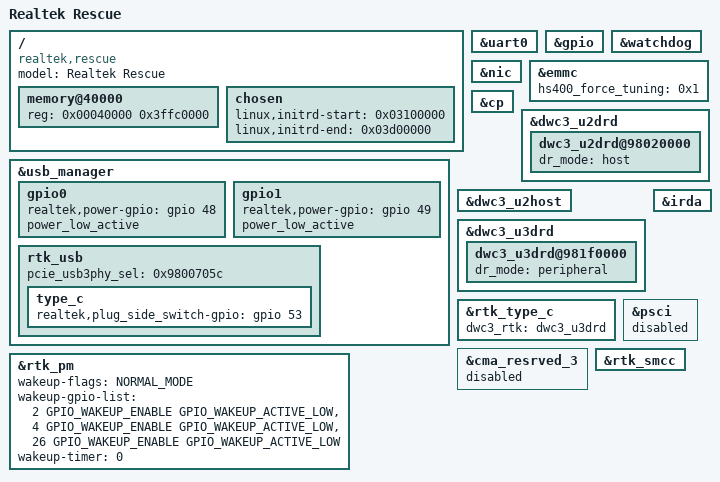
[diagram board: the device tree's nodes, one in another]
// SPDX-License-Identifier: (GPL-2.0-or-later OR BSD-2-Clause)
/*
 * Copyright (c) 2019-2020 Realtek Semiconductor Corp.
 */

/dts-v1/;

#include "rtd13xx.dtsi"
#include <dt-bindings/soc/realtek,pm.h>

/ {
	model = "Realtek Rescue";
	compatible = "realtek,rescue", "realtek,rtd1319";

	memory@40000 {
		device_type = "memory";
		reg = <0x00040000 0x3ffc0000>; /* boot ROM to 1 GiB or 2 GiB */
	};

	chosen {
		linux,initrd-start = <0x03100000>;
		linux,initrd-end = <0x03d00000>;
	};
};

/* debug console (J1) */
&uart0 {
	status = "okay";
};

&gpio {
	status = "okay";
};

&watchdog {
	status = "okay";
};

&nic {
	status = "okay";
};

&emmc {
	hs400_force_tuning = <0x1>;
	status = "okay";
};

&cp {
	status = "okay";
};

&usb_manager {
	status = "okay";

	gpio0 {
		realtek,power-gpio = <&gpio 48 GPIO_ACTIVE_HIGH>;
		power_low_active;
	};

	gpio1 {
		realtek,power-gpio = <&gpio 49 GPIO_ACTIVE_HIGH>;
		power_low_active;
	};

	rtk_usb {
		pcie_usb3phy_sel = <0x9800705c>; /* Only for RTD1319 */
			type_c {
			/* For 1319, u3drd */
			realtek,plug_side_switch-gpio = <&gpio 53 GPIO_ACTIVE_HIGH>;
		};

	};
};

&dwc3_u2drd {
	status = "okay";

	dwc3_u2drd@98020000 {
		dr_mode = "host"; /*host, peripheral*/
		status = "okay";
	};
};

&dwc3_u2host {
	status = "okay";
};

&dwc3_u3drd {
	status = "okay";

	dwc3_u3drd@981f0000 {
		dr_mode = "peripheral"; /*host, peripheral*/
		status = "okay";
	};
};

&rtk_type_c {
	status = "okay";

	dwc3_rtk = <&dwc3_u3drd>;
};

&irda {
	status = "okay";
};

&cma_resrved_3 {
	status = "disabled";
};

&psci {
	status = "disabled";
};

&rtk_pm {
	wakeup-flags = <NORMAL_MODE>;
	wakeup-gpio-list = <2 GPIO_WAKEUP_ENABLE GPIO_WAKEUP_ACTIVE_LOW>,
			   <4 GPIO_WAKEUP_ENABLE GPIO_WAKEUP_ACTIVE_LOW>,
			   <26 GPIO_WAKEUP_ENABLE GPIO_WAKEUP_ACTIVE_LOW>;
	wakeup-timer = <0>;
	status = "okay";
};

&rtk_smcc {
	status = "okay";
};
